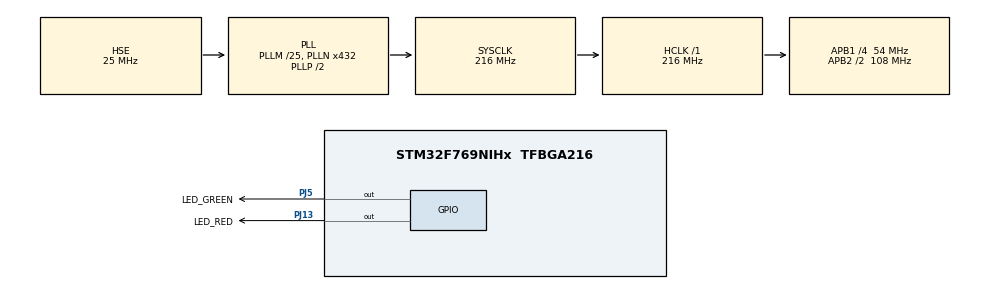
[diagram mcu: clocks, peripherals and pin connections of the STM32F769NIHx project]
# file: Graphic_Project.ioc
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CORTEX_M7.CPU_DCache=Enabled
CORTEX_M7.CPU_ICache=Enabled
CORTEX_M7.FlashInterface=TCM_Enabled
FREERTOS.Tasks01=User_Task1,-2,256,User_Task1_Function,Default,NULL,Dynamic,NULL,NULL
FREERTOS.configCHECK_FOR_STACK_OVERFLOW=2
FREERTOS.configLIBRARY_MAX_SYSCALL_INTERRUPT_PRIORITY=1
FREERTOS.configMINIMAL_STACK_SIZE=256
FREERTOS.configTOTAL_HEAP_SIZE=30720
FREERTOS.configUSE_MALLOC_FAILED_HOOK=1
Mcu.Family=STM32F7
Mcu.Name=STM32F769NIHx
Mcu.Package=TFBGA216
NVIC.PriorityGroup=NVIC_PRIORITYGROUP_4
NVIC.TIM6_DAC_IRQn=true\:0\:0\:false\:false\:true\:false\:false\:true
NVIC.TimeBase=TIM6_DAC_IRQn
NVIC.TimeBaseIP=TIM6
PA13.Mode=Trace_Asynchronous_SW
PA13.Signal=SYS_JTMS-SWDIO
PA14.Mode=Trace_Asynchronous_SW
PA14.Signal=SYS_JTCK-SWCLK
PB3.Mode=Trace_Asynchronous_SW
PB3.Signal=SYS_JTDO-SWO
PH0/OSC_IN.Mode=HSE-External-Oscillator
PH0/OSC_IN.Signal=RCC_OSC_IN
PH1/OSC_OUT.Mode=HSE-External-Oscillator
PH1/OSC_OUT.Signal=RCC_OSC_OUT
PJ13.GPIO_Label=LED_RED
PJ13.GPIO_ModeDefaultOutputPP=GPIO_MODE_OUTPUT_PP
PJ13.GPIO_PuPd=GPIO_NOPULL
PJ13.GPIO_Speed=GPIO_SPEED_FREQ_VERY_HIGH
PJ13.PinState=GPIO_PIN_RESET
PJ13.Signal=GPIO_Output
PJ5.GPIO_Label=LED_GREEN
PJ5.GPIO_ModeDefaultOutputPP=GPIO_MODE_OUTPUT_PP
PJ5.GPIO_PuPd=GPIO_NOPULL
PJ5.GPIO_Speed=GPIO_SPEED_FREQ_VERY_HIGH
PJ5.PinState=GPIO_PIN_RESET
PJ5.Signal=GPIO_Output
ProjectManager.HeapSize=0x200
ProjectManager.StackSize=0x400
ProjectManager.TargetToolchain=TrueSTUDIO
RCC.AHBFreq_Value=216000000
RCC.APB1CLKDivider=RCC_HCLK_DIV4
RCC.APB1Freq_Value=54000000
RCC.APB1TimFreq_Value=108000000
RCC.APB2CLKDivider=RCC_HCLK_DIV2
RCC.APB2Freq_Value=108000000
RCC.APB2TimFreq_Value=216000000
RCC.CortexFreq_Value=216000000
RCC.EnbaleCSS=true
RCC.HCLKFreq_Value=216000000
RCC.HSE_VALUE=25000000
RCC.HSI_VALUE=16000000
RCC.LSE_VALUE=32768
RCC.PLLM=25
RCC.PLLN=432
RCC.PLLSourceVirtual=RCC_PLLSOURCE_HSE
RCC.SYSCLKFreq_VALUE=216000000
RCC.SYSCLKSource=RCC_SYSCLKSOURCE_PLLCLK
RCC.USBFreq_Value=216000000
RCC.VCOOutputFreq_Value=432000000
VP_FREERTOS_VS_CMSIS_V1.Mode=CMSIS_V1
VP_SYS_VS_tim6.Mode=TIM6
board=custom

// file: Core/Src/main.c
/* USER CODE BEGIN Header */
/**
 ******************************************************************************
 * @file           : main.c
 * @brief          : Main program body
 ******************************************************************************
 * @attention
 *
 * <h2><center>&copy; Copyright (c) 2019 STMicroelectronics.
 * All rights reserved.</center></h2>
 *
 * This software component is licensed by ST under Ultimate Liberty license
 * SLA0044, the "License"; You may not use this file except in compliance with
 * the License. You may obtain a copy of the License at:
 *                             www.st.com/SLA0044
 *
 ******************************************************************************
 */
/* USER CODE END Header */

#include "main.h"
#include "cmsis_os.h"
#include "gpio.h"

void SystemClock_Config(void);
void MX_FREERTOS_Init(void);

/* USER CODE BEGIN 0 */
#if(DEBUG_SELECT == DEBUG_TYPE_SWV)

int _write(int file, char *ptr, int len)
{
	int DataIdx;

	for (DataIdx = 0; DataIdx < len; DataIdx++)
	{
		ITM_SendChar(*ptr++);
	}
	return len;
}
#elif (DEBUG_SELECT == DEBUG_TYPE_UART)
#endif

/* USER CODE END 0 */

int main(void)
{
	/* USER CODE BEGIN 1 */
	PrintDebug("\r\nHello Word, Graphic Project STM32 !!!");
	/* USER CODE END 1 */

	/* Enable I-Cache---------------------------------------------------------*/
	SCB_EnableICache();

	/* Enable D-Cache---------------------------------------------------------*/
	SCB_EnableDCache();

	/* MCU Configuration--------------------------------------------------------*/

	/* Reset of all peripherals, Initializes the Flash interface and the Systick. */
	HAL_Init();

	/* Configure the system clock */
	SystemClock_Config();

	/* Initialize all configured peripherals */
	MX_GPIO_Init();

	/* Call init function for freertos objects (in freertos.c) */
	MX_FREERTOS_Init();

	/* Start scheduler */
	osKernelStart();

	/* We should never get here as control is now taken by the scheduler */

	/* Infinite loop */
	while (1)
	{

	}
}

void SystemClock_Config(void)
{
	RCC_OscInitTypeDef RCC_OscInitStruct = {0};
	RCC_ClkInitTypeDef RCC_ClkInitStruct = {0};

	/** Configure the main internal regulator output voltage
	 */
	__HAL_RCC_PWR_CLK_ENABLE();
	__HAL_PWR_VOLTAGESCALING_CONFIG(PWR_REGULATOR_VOLTAGE_SCALE1);
	/** Initializes the CPU, AHB and APB busses clocks
	 */
	RCC_OscInitStruct.OscillatorType = RCC_OSCILLATORTYPE_HSE;
	RCC_OscInitStruct.HSEState = RCC_HSE_ON;
	RCC_OscInitStruct.PLL.PLLState = RCC_PLL_ON;
	RCC_OscInitStruct.PLL.PLLSource = RCC_PLLSOURCE_HSE;
	RCC_OscInitStruct.PLL.PLLM = 25;
	RCC_OscInitStruct.PLL.PLLN = 432;
	RCC_OscInitStruct.PLL.PLLP = RCC_PLLP_DIV2;
	RCC_OscInitStruct.PLL.PLLQ = 2;
	if (HAL_RCC_OscConfig(&RCC_OscInitStruct) != HAL_OK)
	{
		Error_Handler();
	}
	/** Activate the Over-Drive mode
	 */
	if (HAL_PWREx_EnableOverDrive() != HAL_OK)
	{
		Error_Handler();
	}
	/** Initializes the CPU, AHB and APB busses clocks
	 */
	RCC_ClkInitStruct.ClockType = RCC_CLOCKTYPE_HCLK|RCC_CLOCKTYPE_SYSCLK
			|RCC_CLOCKTYPE_PCLK1|RCC_CLOCKTYPE_PCLK2;
	RCC_ClkInitStruct.SYSCLKSource = RCC_SYSCLKSOURCE_PLLCLK;
	RCC_ClkInitStruct.AHBCLKDivider = RCC_SYSCLK_DIV1;
	RCC_ClkInitStruct.APB1CLKDivider = RCC_HCLK_DIV4;
	RCC_ClkInitStruct.APB2CLKDivider = RCC_HCLK_DIV2;

	if (HAL_RCC_ClockConfig(&RCC_ClkInitStruct, FLASH_LATENCY_7) != HAL_OK)
	{
		Error_Handler();
	}
	/** Enables the Clock Security System
	 */
	HAL_RCC_EnableCSS();
}

void HAL_TIM_PeriodElapsedCallback(TIM_HandleTypeDef *htim)
{
	if (htim->Instance == TIM6) {
		HAL_IncTick();
	}
}

void Error_Handler(void)
{
}

/************************ (C) COPYRIGHT STMicroelectronics *****END OF FILE****/

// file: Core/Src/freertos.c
/* USER CODE BEGIN Header */
/**
 ******************************************************************************
 * File Name          : freertos.c
 * Description        : Code for freertos applications
 ******************************************************************************
 * @attention
 *
 * <h2><center>&copy; Copyright (c) 2019 STMicroelectronics.
 * All rights reserved.</center></h2>
 *
 * This software component is licensed by ST under Ultimate Liberty license
 * SLA0044, the "License"; You may not use this file except in compliance with
 * the License. You may obtain a copy of the License at:
 *                             www.st.com/SLA0044
 *
 ******************************************************************************
 */
/* USER CODE END Header */

#include "FreeRTOS.h"
#include "task.h"
#include "main.h"
#include "cmsis_os.h"

osThreadId User_Task1Handle;

void User_Task1_Function(void const * argument);

void MX_FREERTOS_Init(void); /* (MISRA C 2004 rule 8.1) */

/* Hook prototypes */
void vApplicationStackOverflowHook(xTaskHandle xTask, signed char *pcTaskName);
void vApplicationMallocFailedHook(void);

/* USER CODE BEGIN 4 */
__weak void vApplicationStackOverflowHook(xTaskHandle xTask, signed char *pcTaskName)
{
	/* Run time stack overflow checking is performed if
   configCHECK_FOR_STACK_OVERFLOW is defined to 1 or 2. This hook function is
   called if a stack overflow is detected. */
}
/* USER CODE END 4 */

/* USER CODE BEGIN 5 */
__weak void vApplicationMallocFailedHook(void)
{
	/* vApplicationMallocFailedHook() will only be called if
   configUSE_MALLOC_FAILED_HOOK is set to 1 in FreeRTOSConfig.h. It is a hook
   function that will get called if a call to pvPortMalloc() fails.
   pvPortMalloc() is called internally by the kernel whenever a task, queue,
   timer or semaphore is created. It is also called by various parts of the
   demo application. If heap_1.c or heap_2.c are used, then the size of the
   heap available to pvPortMalloc() is defined by configTOTAL_HEAP_SIZE in
   FreeRTOSConfig.h, and the xPortGetFreeHeapSize() API function can be used
   to query the size of free heap space that remains (although it does not
   provide information on how the remaining heap might be fragmented). */
}
/* USER CODE END 5 */

void MX_FREERTOS_Init(void) {

  /* Create the thread(s) */
  /* definition and creation of User_Task1 */
  osThreadDef(User_Task1, User_Task1_Function, osPriorityLow, 0, 256);
  User_Task1Handle = osThreadCreate(osThread(User_Task1), NULL);

}

void User_Task1_Function(void const * argument)
{

  /* USER CODE BEGIN User_Task1_Function */
	PrintDebug("\r\nUser Task1 Function Enter");
	/* Infinite loop */
	for(;;)
	{
		PrintDebug("\r\nLED change.");
		HAL_GPIO_TogglePin(LED_RED_GPIO_Port,LED_RED_Pin | LED_GREEN_Pin);
		osDelay(500);
	}
  /* USER CODE END User_Task1_Function */
}

/************************ (C) COPYRIGHT STMicroelectronics *****END OF FILE****/
